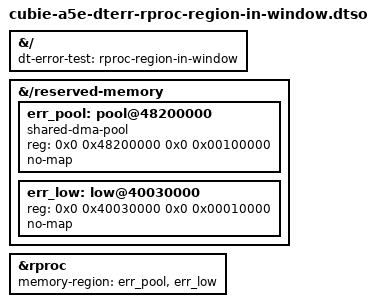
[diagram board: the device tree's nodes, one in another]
/dts-v1/;
/plugin/;

/*
 * DT error test for the A5E message box / remoteproc probe (tools/dt_error_tests.sh).
 * Applied after cubie-a5e-flight-stack; replaces one property so that one probe
 * check fails. Test only: never in a normal boot.
 */

#include <dt-bindings/clock/sun55i-a523-ccu.h>
#include <dt-bindings/clock/sun55i-a523-mcu-ccu.h>
#include <dt-bindings/clock/sun55i-a523-r-ccu.h>
#include <dt-bindings/reset/sun55i-a523-ccu.h>
#include <dt-bindings/reset/sun55i-a523-mcu-ccu.h>
#include <dt-bindings/reset/sun55i-a523-r-ccu.h>

/* The test script reads this back to see that U-Boot applied the overlay */
&{/} {
	dt-error-test = "rproc-region-in-window";
};

/* A pool of our own: labels from other overlays are not visible here */
&{/reserved-memory} {
	#address-cells = <2>;
	#size-cells = <2>;

	err_pool: pool@48200000 {
		compatible = "shared-dma-pool";
		reg = <0x0 0x48200000 0x0 0x00100000>;
		no-map;
	};

	/* DRAM at 0x40000000 is where the core sees SRAM space 1 */
	err_low: low@40030000 {
		reg = <0x0 0x40030000 0x0 0x00010000>;
		no-map;
	};
};

&rproc {
	memory-region = <&err_pool>, <&err_low>;
};
